# K32W061 register map
Vendor: nxp.com; File version: 1.0
CPU: CM4 r0p1, little endian, MPU, no FPU, VTOR, 3 interrupt priority bits
Registers are 32-bit, read-write, reset 0x0 unless marked. A register's access mark holds for its fields unless they carry their own. Offsets are from the block's base; [hi:lo] are bit positions.

## OTPC — This is the description of component otpc It is an eFUSE OTP (One Time Programmable memory) controller with APB bus interface. More details will follow.
Base 0x40002000
0x00 ADDR — Address register for reading the E-Fuse OTP
  [11:0] ADDR — Address of OTP value to be read
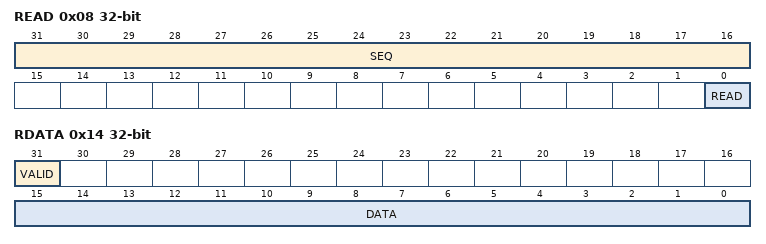
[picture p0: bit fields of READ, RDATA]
0x08 READ reset not defined — Register for reading the E-Fuse OTP.
  [31:16] SEQ wo — Read unlock sequence: only when 0x7F12 is written is the Read command accepted.
  [0] READ wo — When 1 is written, the OTP is read. Note, this operation only occurs if correct SEQ value is also written.
0x14 RDATA ro — Register for the OTP read back data.
  [31] VALID — Valid bit. This bit will be cleared when a Read command has been given and will be set when the sequencer has successfully captured the E-Fuse OTP data.
  [15:0] DATA — Read back data from the E-Fuse OTP.

## RTC — This is the description of component rtc It is Real Time Clock with APB bus interface. More details will follow.
Base 0x4000B000
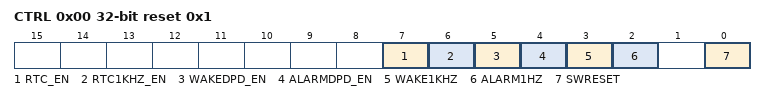
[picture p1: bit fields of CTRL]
0x00 CTRL reset 0x1 — RTC control register
  [7] RTC_EN — RTC enable. 0: Disable. The RTC 32-bit timer and 16-bit timer clocks are shut down and the RTC operation is disabled. This bit should be 0 when writing to load a value in the RTC counter register. 1: Enable. The 32-bit RTC clock is running and RTC operation is enabled. This bit must be set to initiate operation of the RTC. To also enable the 16-bit timer clock, set bit 6 in this register.
  [6] RTC1KHZ_EN — RTC 16-bit timer clock enable. This bit can be set to 0 to conserve power if the 16-bit timer is not used. This bit has no effect when the RTC is disabled (bit 7 of this register is 0). 0: Disable. A match on the 16-bit RTC timer will not bring the part out of Deep power-down mode. 1: Enable. The 16-bit RTC timer is enabled.
  [5] WAKEDPD_EN — RTC 16-bit timer wake-up enable for power-down modes. 0: Disable. A match on the 16-bit RTC timer will not bring the part out of power-down modes. 1: Enable. A match on the 16-bit RTC timer will bring the part out of power-down modes.
  [4] ALARMDPD_EN — RTC 32-bit timer alarm enable for Low power mode. 0: Disable. A match on the 32-bit RTC timer will not bring the part out of power-down modes. 1: Enable. A match on the 32-bit RTC timer will bring the part out of power-down modes.
  [3] WAKE1KHZ — RTC 16-bit timer wake-up flag status. 0: The RTC 16-bit timer is running. Writing a 0 has no effect. 1: The 16-bit timer has timed out. This flag generates an RTC wake-up interrupt request RTC-WAKE which can also wake up the part from low power modes (excluding deep power down mode). Writing a 1 clears this bit.
  [2] ALARM1HZ — RTC 32-bit timer alarm flag status. 0: No match has occurred on the 32-bit RTC timer. Writing a 0 has no effect. 1: A match condition has occurred on the 32-bit RTC timer. This flag generates an RTC alarm interrupt request. RTC_ALARM which can also wake up the part from low power modes (excluding deep power down mode). Writing a 1 clears this bit.
  [0] SWRESET — Software reset control. 0: Not in reset. The RTC is not held in reset. This bit must be cleared prior to configuring or initiating any operation of the RTC. 1: In reset. The RTC is held in reset. All register bits within the RTC will be forced to their reset value except the OFD bit. This bit must be cleared before writing to any register in the RTC - including writes to set any of the other bits within this register. Do not attempt to write to any bits of this register at the same time that the reset bit is being cleared.
0x04 MATCH reset 0xFFFFFFFF — RTC 32-bit counter match register
  [31:0] MATVAL — Contains the match value against which the 1 Hz RTC timer will be compared to generate the alarm flag RTC_ALARM and generate an alarm interrupt/wake-up if enabled.
0x08 COUNT — RTC 32-bit counter register
  [31:0] VAL — A read reflects the current value of the main, 32-bit, RTC timer. A write loads a new initial value into the timer. The RTC 32-bit counter will count up continuously at the 32-bit timer clock rate once the RTC Software Reset is removed (by clearing bit 0 of the CTRL register). Remark: Only write to this register when the RTC_EN bit in the RTC CTRL Register is 0.
0x0C WAKE — 16-bit RTC timer register
  [15:0] VAL — A read reflects the current value of 16-bit timer. A write pre-loads a start count value into the 16-bit timer and initializes a count-down sequence. Do not write to this register while counting is in progress.
